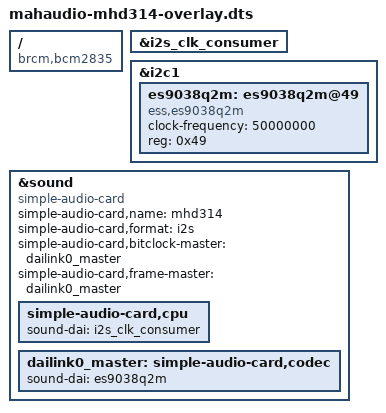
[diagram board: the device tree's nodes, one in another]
/dts-v1/;
/plugin/;

/ {
    compatible = "brcm,bcm2835";

    fragment@0 {
        target = <&i2s_clk_consumer>;
        __overlay__ {
            status = "okay";
        };
    };

    fragment@1 {
        target = <&i2c1>;
        __overlay__ {
            #address-cells = <1>;
            #size-cells = <0>;
            status = "okay";
            
            es9038q2m: es9038q2m@49 {
                compatible = "ess,es9038q2m";
                status = "okay";
                clock-frequency = <50000000>;
                reg = <0x49>;
                #sound-dai-cells = <0>;
            };
        };
    };

    fragment@2 {
        target = <&sound>;
        sound_overlay: __overlay__ {
            compatible = "simple-audio-card";
            simple-audio-card,name = "mhd314";
            status = "okay";
            
            simple-audio-card,format = "i2s";
            simple-audio-card,bitclock-master = <&dailink0_master>;
            simple-audio-card,frame-master = <&dailink0_master>;

            simple-audio-card,cpu {
                sound-dai = <&i2s_clk_consumer>;
            };
            dailink0_master: simple-audio-card,codec {
                sound-dai = <&es9038q2m>;
                
                
            };
        };
    };
};
